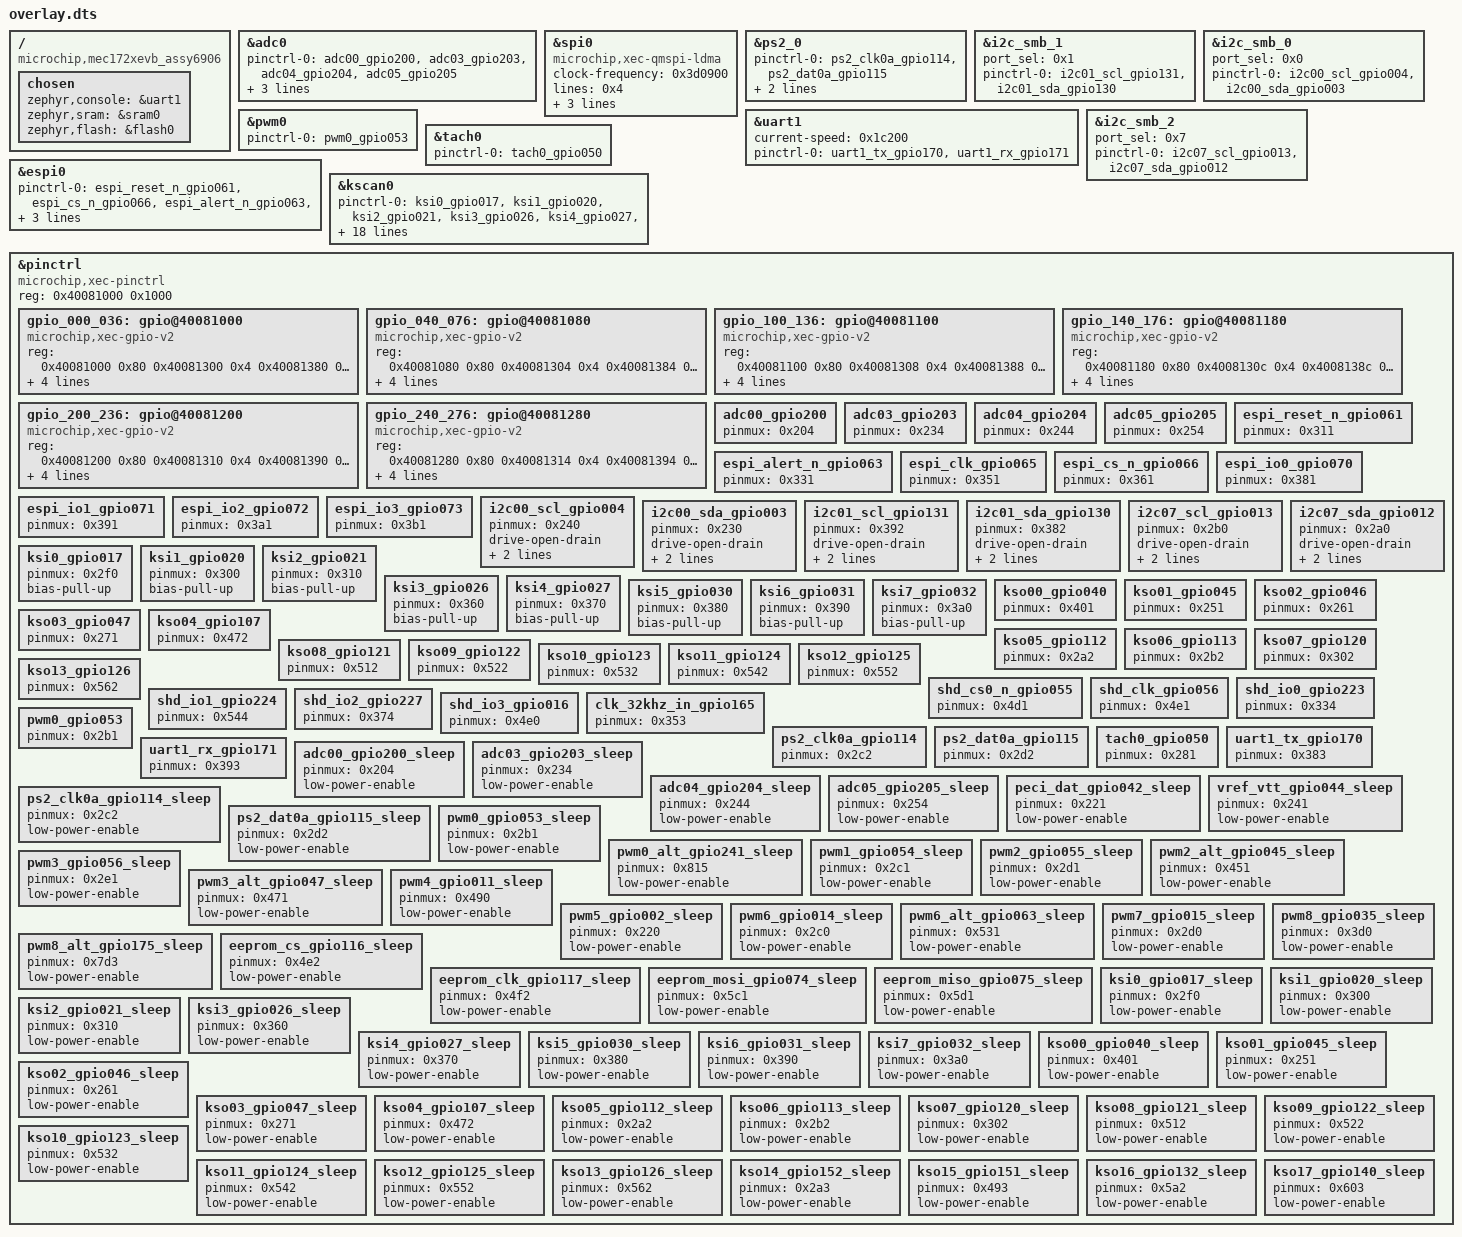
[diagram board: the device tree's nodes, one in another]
/ {
	compatible = "microchip,mec172xevb_assy6906", "microchip,mec172xnsz";
	chosen {
		zephyr,console = &uart1;
		zephyr,sram = &sram0;
		zephyr,flash = &flash0;
	};
};
&adc0{
	status = "okay";
	pinctrl-0 = < &adc00_gpio200 &adc03_gpio203 &adc04_gpio204 &adc05_gpio205 >;
	pinctrl-1 = < &adc00_gpio200_sleep &adc03_gpio203_sleep &adc04_gpio204_sleep &adc05_gpio205_sleep >;
	pinctrl-names = "default", "sleep";
};
&spi0{
	clock-frequency = < 0x3d0900 >;
	lines = < 0x4 >;
	status = "okay";
	compatible = "microchip,xec-qmspi-ldma";
	pinctrl-0 = < &shd_cs0_n_gpio055 &shd_clk_gpio056 &shd_io0_gpio223 &shd_io1_gpio224 &shd_io2_gpio227 &shd_io3_gpio016 >;
	pinctrl-names = "default";
};
&ps2_0{
	status = "okay";
	pinctrl-0 = < &ps2_clk0a_gpio114 &ps2_dat0a_gpio115 >;
	pinctrl-1 = < &ps2_clk0a_gpio114_sleep &ps2_dat0a_gpio115_sleep >;
	pinctrl-names = "default", "sleep";
};
&i2c_smb_1{
	status = "okay";
	port_sel = < 0x1 >;
	pinctrl-0 = < &i2c01_scl_gpio131 &i2c01_sda_gpio130 >;
	pinctrl-names = "default";
};
&i2c_smb_0{
	status = "okay";
	port_sel = < 0x0 >;
	pinctrl-0 = < &i2c00_scl_gpio004 &i2c00_sda_gpio003 >;
	pinctrl-names = "default";
};
&pwm0{
	status = "okay";
	pinctrl-0 = < &pwm0_gpio053 >;
	pinctrl-names = "default";
};
&uart1{
	current-speed = < 0x1c200 >;
	status = "okay";
	pinctrl-0 = < &uart1_tx_gpio170 &uart1_rx_gpio171 >;
	pinctrl-names = "default";
};
&i2c_smb_2{
	status = "okay";
	port_sel = < 0x7 >;
	pinctrl-0 = < &i2c07_scl_gpio013 &i2c07_sda_gpio012 >;
	pinctrl-names = "default";
};
&tach0{
	status = "okay";
	pinctrl-0 = < &tach0_gpio050 >;
	pinctrl-names = "default";
};
&espi0{
	status = "okay";
	pinctrl-0 = < &espi_reset_n_gpio061 &espi_cs_n_gpio066 &espi_alert_n_gpio063 &espi_clk_gpio065 &espi_io0_gpio070 &espi_io1_gpio071 &espi_io2_gpio072 &espi_io3_gpio073 >;
	pinctrl-names = "default";
};
&kscan0{
	status = "okay";
	pinctrl-0 = < &ksi0_gpio017 &ksi1_gpio020 &ksi2_gpio021 &ksi3_gpio026 &ksi4_gpio027 &ksi5_gpio030 &ksi6_gpio031 &ksi7_gpio032 &kso00_gpio040 &kso01_gpio045 &kso02_gpio046 &kso03_gpio047 &kso04_gpio107 &kso05_gpio112 &kso06_gpio113 &kso07_gpio120 &kso08_gpio121 &kso09_gpio122 &kso10_gpio123 &kso11_gpio124 &kso12_gpio125 &kso13_gpio126 >;
	pinctrl-1 = < &ksi0_gpio017_sleep &ksi1_gpio020_sleep &ksi2_gpio021_sleep &ksi3_gpio026_sleep &ksi4_gpio027_sleep &ksi5_gpio030_sleep &ksi6_gpio031_sleep &ksi7_gpio032_sleep &kso00_gpio040_sleep &kso01_gpio045_sleep &kso02_gpio046_sleep &kso03_gpio047_sleep &kso04_gpio107_sleep &kso05_gpio112_sleep &kso06_gpio113_sleep &kso07_gpio120_sleep &kso08_gpio121_sleep &kso09_gpio122_sleep &kso10_gpio123_sleep &kso11_gpio124_sleep &kso12_gpio125_sleep &kso13_gpio126_sleep >;
	pinctrl-names = "default", "sleep";
};
&pinctrl{
	compatible = "microchip,xec-pinctrl";
	#address-cells = < 0x1 >;
	#size-cells = < 0x1 >;
	reg = < 0x40081000 0x1000 >;
	gpio_000_036: gpio@40081000 {
		compatible = "microchip,xec-gpio-v2";
		reg = < 0x40081000 0x80 0x40081300 0x4 0x40081380 0x4 0x400813fc 0x4 >;
		interrupts = < 0x3 0x2 >;
		gpio-controller;
		port-id = < 0x0 >;
		girq-id = < 0xb >;
		#gpio-cells = < 0x2 >;
	};
	gpio_040_076: gpio@40081080 {
		compatible = "microchip,xec-gpio-v2";
		reg = < 0x40081080 0x80 0x40081304 0x4 0x40081384 0x4 0x400813f8 0x4 >;
		interrupts = < 0x2 0x2 >;
		gpio-controller;
		port-id = < 0x1 >;
		girq-id = < 0xa >;
		#gpio-cells = < 0x2 >;
	};
	gpio_100_136: gpio@40081100 {
		compatible = "microchip,xec-gpio-v2";
		reg = < 0x40081100 0x80 0x40081308 0x4 0x40081388 0x4 0x400813f4 0x4 >;
		gpio-controller;
		interrupts = < 0x1 0x2 >;
		port-id = < 0x2 >;
		girq-id = < 0x9 >;
		#gpio-cells = < 0x2 >;
	};
	gpio_140_176: gpio@40081180 {
		compatible = "microchip,xec-gpio-v2";
		reg = < 0x40081180 0x80 0x4008130c 0x4 0x4008138c 0x4 0x400813f0 0x4 >;
		gpio-controller;
		interrupts = < 0x0 0x2 >;
		port-id = < 0x3 >;
		girq-id = < 0x8 >;
		#gpio-cells = < 0x2 >;
	};
	gpio_200_236: gpio@40081200 {
		compatible = "microchip,xec-gpio-v2";
		reg = < 0x40081200 0x80 0x40081310 0x4 0x40081390 0x4 0x400813ec 0x4 >;
		gpio-controller;
		interrupts = < 0x4 0x2 >;
		port-id = < 0x4 >;
		girq-id = < 0xc >;
		#gpio-cells = < 0x2 >;
	};
	gpio_240_276: gpio@40081280 {
		compatible = "microchip,xec-gpio-v2";
		reg = < 0x40081280 0x80 0x40081314 0x4 0x40081394 0x4 0x400813e8 0x4 >;
		gpio-controller;
		interrupts = < 0x11 0x2 >;
		port-id = < 0x5 >;
		girq-id = < 0x1a >;
		#gpio-cells = < 0x2 >;
	};
	adc00_gpio200: adc00_gpio200 {
		pinmux = < 0x204 >;
	};
	adc03_gpio203: adc03_gpio203 {
		pinmux = < 0x234 >;
	};
	adc04_gpio204: adc04_gpio204 {
		pinmux = < 0x244 >;
	};
	adc05_gpio205: adc05_gpio205 {
		pinmux = < 0x254 >;
	};
	espi_reset_n_gpio061: espi_reset_n_gpio061 {
		pinmux = < 0x311 >;
	};
	espi_alert_n_gpio063: espi_alert_n_gpio063 {
		pinmux = < 0x331 >;
	};
	espi_clk_gpio065: espi_clk_gpio065 {
		pinmux = < 0x351 >;
	};
	espi_cs_n_gpio066: espi_cs_n_gpio066 {
		pinmux = < 0x361 >;
	};
	espi_io0_gpio070: espi_io0_gpio070 {
		pinmux = < 0x381 >;
	};
	espi_io1_gpio071: espi_io1_gpio071 {
		pinmux = < 0x391 >;
	};
	espi_io2_gpio072: espi_io2_gpio072 {
		pinmux = < 0x3a1 >;
	};
	espi_io3_gpio073: espi_io3_gpio073 {
		pinmux = < 0x3b1 >;
	};
	i2c00_scl_gpio004: i2c00_scl_gpio004 {
		pinmux = < 0x240 >;
		drive-open-drain;
		output-enable;
		output-high;
	};
	i2c00_sda_gpio003: i2c00_sda_gpio003 {
		pinmux = < 0x230 >;
		drive-open-drain;
		output-enable;
		output-high;
	};
	i2c01_scl_gpio131: i2c01_scl_gpio131 {
		pinmux = < 0x392 >;
		drive-open-drain;
		output-enable;
		output-high;
	};
	i2c01_sda_gpio130: i2c01_sda_gpio130 {
		pinmux = < 0x382 >;
		drive-open-drain;
		output-enable;
		output-high;
	};
	i2c07_scl_gpio013: i2c07_scl_gpio013 {
		pinmux = < 0x2b0 >;
		drive-open-drain;
		output-enable;
		output-high;
	};
	i2c07_sda_gpio012: i2c07_sda_gpio012 {
		pinmux = < 0x2a0 >;
		drive-open-drain;
		output-enable;
		output-high;
	};
	ksi0_gpio017: ksi0_gpio017 {
		pinmux = < 0x2f0 >;
		bias-pull-up;
	};
	ksi1_gpio020: ksi1_gpio020 {
		pinmux = < 0x300 >;
		bias-pull-up;
	};
	ksi2_gpio021: ksi2_gpio021 {
		pinmux = < 0x310 >;
		bias-pull-up;
	};
	ksi3_gpio026: ksi3_gpio026 {
		pinmux = < 0x360 >;
		bias-pull-up;
	};
	ksi4_gpio027: ksi4_gpio027 {
		pinmux = < 0x370 >;
		bias-pull-up;
	};
	ksi5_gpio030: ksi5_gpio030 {
		pinmux = < 0x380 >;
		bias-pull-up;
	};
	ksi6_gpio031: ksi6_gpio031 {
		pinmux = < 0x390 >;
		bias-pull-up;
	};
	ksi7_gpio032: ksi7_gpio032 {
		pinmux = < 0x3a0 >;
		bias-pull-up;
	};
	kso00_gpio040: kso00_gpio040 {
		pinmux = < 0x401 >;
	};
	kso01_gpio045: kso01_gpio045 {
		pinmux = < 0x251 >;
	};
	kso02_gpio046: kso02_gpio046 {
		pinmux = < 0x261 >;
	};
	kso03_gpio047: kso03_gpio047 {
		pinmux = < 0x271 >;
	};
	kso04_gpio107: kso04_gpio107 {
		pinmux = < 0x472 >;
	};
	kso05_gpio112: kso05_gpio112 {
		pinmux = < 0x2a2 >;
	};
	kso06_gpio113: kso06_gpio113 {
		pinmux = < 0x2b2 >;
	};
	kso07_gpio120: kso07_gpio120 {
		pinmux = < 0x302 >;
	};
	kso08_gpio121: kso08_gpio121 {
		pinmux = < 0x512 >;
	};
	kso09_gpio122: kso09_gpio122 {
		pinmux = < 0x522 >;
	};
	kso10_gpio123: kso10_gpio123 {
		pinmux = < 0x532 >;
	};
	kso11_gpio124: kso11_gpio124 {
		pinmux = < 0x542 >;
	};
	kso12_gpio125: kso12_gpio125 {
		pinmux = < 0x552 >;
	};
	kso13_gpio126: kso13_gpio126 {
		pinmux = < 0x562 >;
	};
	shd_cs0_n_gpio055: shd_cs0_n_gpio055 {
		pinmux = < 0x4d1 >;
	};
	shd_clk_gpio056: shd_clk_gpio056 {
		pinmux = < 0x4e1 >;
	};
	shd_io0_gpio223: shd_io0_gpio223 {
		pinmux = < 0x334 >;
	};
	shd_io1_gpio224: shd_io1_gpio224 {
		pinmux = < 0x544 >;
	};
	shd_io2_gpio227: shd_io2_gpio227 {
		pinmux = < 0x374 >;
	};
	shd_io3_gpio016: shd_io3_gpio016 {
		pinmux = < 0x4e0 >;
	};
	clk_32khz_in_gpio165: clk_32khz_in_gpio165 {
		pinmux = < 0x353 >;
	};
	ps2_clk0a_gpio114: ps2_clk0a_gpio114 {
		pinmux = < 0x2c2 >;
	};
	ps2_dat0a_gpio115: ps2_dat0a_gpio115 {
		pinmux = < 0x2d2 >;
	};
	pwm0_gpio053: pwm0_gpio053 {
		pinmux = < 0x2b1 >;
	};
	tach0_gpio050: tach0_gpio050 {
		pinmux = < 0x281 >;
	};
	uart1_tx_gpio170: uart1_tx_gpio170 {
		pinmux = < 0x383 >;
	};
	uart1_rx_gpio171: uart1_rx_gpio171 {
		pinmux = < 0x393 >;
	};
	adc00_gpio200_sleep: adc00_gpio200_sleep {
		pinmux = < 0x204 >;
		low-power-enable;
	};
	adc03_gpio203_sleep: adc03_gpio203_sleep {
		pinmux = < 0x234 >;
		low-power-enable;
	};
	adc04_gpio204_sleep: adc04_gpio204_sleep {
		pinmux = < 0x244 >;
		low-power-enable;
	};
	adc05_gpio205_sleep: adc05_gpio205_sleep {
		pinmux = < 0x254 >;
		low-power-enable;
	};
	peci_dat_gpio042_sleep: peci_dat_gpio042_sleep {
		pinmux = < 0x221 >;
		low-power-enable;
	};
	vref_vtt_gpio044_sleep: vref_vtt_gpio044_sleep {
		pinmux = < 0x241 >;
		low-power-enable;
	};
	ps2_clk0a_gpio114_sleep: ps2_clk0a_gpio114_sleep {
		pinmux = < 0x2c2 >;
		low-power-enable;
	};
	ps2_dat0a_gpio115_sleep: ps2_dat0a_gpio115_sleep {
		pinmux = < 0x2d2 >;
		low-power-enable;
	};
	pwm0_gpio053_sleep: pwm0_gpio053_sleep {
		pinmux = < 0x2b1 >;
		low-power-enable;
	};
	pwm0_alt_gpio241_sleep: pwm0_alt_gpio241_sleep {
		pinmux = < 0x815 >;
		low-power-enable;
	};
	pwm1_gpio054_sleep: pwm1_gpio054_sleep {
		pinmux = < 0x2c1 >;
		low-power-enable;
	};
	pwm2_gpio055_sleep: pwm2_gpio055_sleep {
		pinmux = < 0x2d1 >;
		low-power-enable;
	};
	pwm2_alt_gpio045_sleep: pwm2_alt_gpio045_sleep {
		pinmux = < 0x451 >;
		low-power-enable;
	};
	pwm3_gpio056_sleep: pwm3_gpio056_sleep {
		pinmux = < 0x2e1 >;
		low-power-enable;
	};
	pwm3_alt_gpio047_sleep: pwm3_alt_gpio047_sleep {
		pinmux = < 0x471 >;
		low-power-enable;
	};
	pwm4_gpio011_sleep: pwm4_gpio011_sleep {
		pinmux = < 0x490 >;
		low-power-enable;
	};
	pwm5_gpio002_sleep: pwm5_gpio002_sleep {
		pinmux = < 0x220 >;
		low-power-enable;
	};
	pwm6_gpio014_sleep: pwm6_gpio014_sleep {
		pinmux = < 0x2c0 >;
		low-power-enable;
	};
	pwm6_alt_gpio063_sleep: pwm6_alt_gpio063_sleep {
		pinmux = < 0x531 >;
		low-power-enable;
	};
	pwm7_gpio015_sleep: pwm7_gpio015_sleep {
		pinmux = < 0x2d0 >;
		low-power-enable;
	};
	pwm8_gpio035_sleep: pwm8_gpio035_sleep {
		pinmux = < 0x3d0 >;
		low-power-enable;
	};
	pwm8_alt_gpio175_sleep: pwm8_alt_gpio175_sleep {
		pinmux = < 0x7d3 >;
		low-power-enable;
	};
	eeprom_cs_gpio116_sleep: eeprom_cs_gpio116_sleep {
		pinmux = < 0x4e2 >;
		low-power-enable;
	};
	eeprom_clk_gpio117_sleep: eeprom_clk_gpio117_sleep {
		pinmux = < 0x4f2 >;
		low-power-enable;
	};
	eeprom_mosi_gpio074_sleep: eeprom_mosi_gpio074_sleep {
		pinmux = < 0x5c1 >;
		low-power-enable;
	};
	eeprom_miso_gpio075_sleep: eeprom_miso_gpio075_sleep {
		pinmux = < 0x5d1 >;
		low-power-enable;
	};
	ksi0_gpio017_sleep: ksi0_gpio017_sleep {
		pinmux = < 0x2f0 >;
		low-power-enable;
	};
	ksi1_gpio020_sleep: ksi1_gpio020_sleep {
		pinmux = < 0x300 >;
		low-power-enable;
	};
	ksi2_gpio021_sleep: ksi2_gpio021_sleep {
		pinmux = < 0x310 >;
		low-power-enable;
	};
	ksi3_gpio026_sleep: ksi3_gpio026_sleep {
		pinmux = < 0x360 >;
		low-power-enable;
	};
	ksi4_gpio027_sleep: ksi4_gpio027_sleep {
		pinmux = < 0x370 >;
		low-power-enable;
	};
	ksi5_gpio030_sleep: ksi5_gpio030_sleep {
		pinmux = < 0x380 >;
		low-power-enable;
	};
	ksi6_gpio031_sleep: ksi6_gpio031_sleep {
		pinmux = < 0x390 >;
		low-power-enable;
	};
	ksi7_gpio032_sleep: ksi7_gpio032_sleep {
		pinmux = < 0x3a0 >;
		low-power-enable;
	};
	kso00_gpio040_sleep: kso00_gpio040_sleep {
		pinmux = < 0x401 >;
		low-power-enable;
	};
	kso01_gpio045_sleep: kso01_gpio045_sleep {
		pinmux = < 0x251 >;
		low-power-enable;
	};
	kso02_gpio046_sleep: kso02_gpio046_sleep {
		pinmux = < 0x261 >;
		low-power-enable;
	};
	kso03_gpio047_sleep: kso03_gpio047_sleep {
		pinmux = < 0x271 >;
		low-power-enable;
	};
	kso04_gpio107_sleep: kso04_gpio107_sleep {
		pinmux = < 0x472 >;
		low-power-enable;
	};
	kso05_gpio112_sleep: kso05_gpio112_sleep {
		pinmux = < 0x2a2 >;
		low-power-enable;
	};
	kso06_gpio113_sleep: kso06_gpio113_sleep {
		pinmux = < 0x2b2 >;
		low-power-enable;
	};
	kso07_gpio120_sleep: kso07_gpio120_sleep {
		pinmux = < 0x302 >;
		low-power-enable;
	};
	kso08_gpio121_sleep: kso08_gpio121_sleep {
		pinmux = < 0x512 >;
		low-power-enable;
	};
	kso09_gpio122_sleep: kso09_gpio122_sleep {
		pinmux = < 0x522 >;
		low-power-enable;
	};
	kso10_gpio123_sleep: kso10_gpio123_sleep {
		pinmux = < 0x532 >;
		low-power-enable;
	};
	kso11_gpio124_sleep: kso11_gpio124_sleep {
		pinmux = < 0x542 >;
		low-power-enable;
	};
	kso12_gpio125_sleep: kso12_gpio125_sleep {
		pinmux = < 0x552 >;
		low-power-enable;
	};
	kso13_gpio126_sleep: kso13_gpio126_sleep {
		pinmux = < 0x562 >;
		low-power-enable;
	};
	kso14_gpio152_sleep: kso14_gpio152_sleep {
		pinmux = < 0x2a3 >;
		low-power-enable;
	};
	kso15_gpio151_sleep: kso15_gpio151_sleep {
		pinmux = < 0x493 >;
		low-power-enable;
	};
	kso16_gpio132_sleep: kso16_gpio132_sleep {
		pinmux = < 0x5a2 >;
		low-power-enable;
	};
	kso17_gpio140_sleep: kso17_gpio140_sleep {
		pinmux = < 0x603 >;
		low-power-enable;
	};
};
